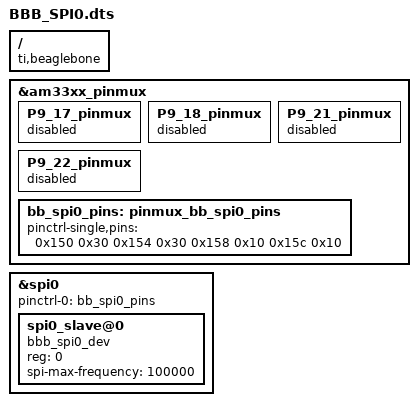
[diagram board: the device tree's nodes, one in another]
/dts-v1/;
/plugin/;

/ {
	compatible = "ti,beaglebone", "ti,beaglebone-black";
	
	fragment@0 {
		target = <&am33xx_pinmux>;
		__overlay__ {
			P9_17_pinmux {
                status = "disabled";
            };
            P9_18_pinmux {
                status = "disabled";
            };
            P9_21_pinmux {
                status = "disabled";
            };
            P9_22_pinmux {
                status = "disabled";
            };
			
			bb_spi0_pins: pinmux_bb_spi0_pins {
				pinctrl-single,pins = <
					0x150 0x30	/* spi0_sclk.spi0_sclk,	INPUT_PULLUP	| MODE0 */
					0x154 0x30	/* spi0_d0.spi0_d0,		INPUT_PULLUP	| MODE0 */
					0x158 0x10	/* spi0_d1.spi0_d1,		OUTPUT_PULLUP	| MODE0 */
					0x15c 0x10	/* spi0_cs0.spi0_cs0,	OUTPUT_PULLUP	| MODE0 */
				>;
			};
		};
	};

	fragment@1 {
		target = <&spi0>;
		__overlay__ {
			status = "okay";
			pinctrl-names = "default";
			pinctrl-0 = <&bb_spi0_pins>;

			#address-cells = <1>;
			#size-cells = <0>;
			
			spi0_slave@0 {
				compatible = "bbb_spi0_dev";
				reg = <0>;
				spi-max-frequency = <100000>;
			};
		};
	};
};
